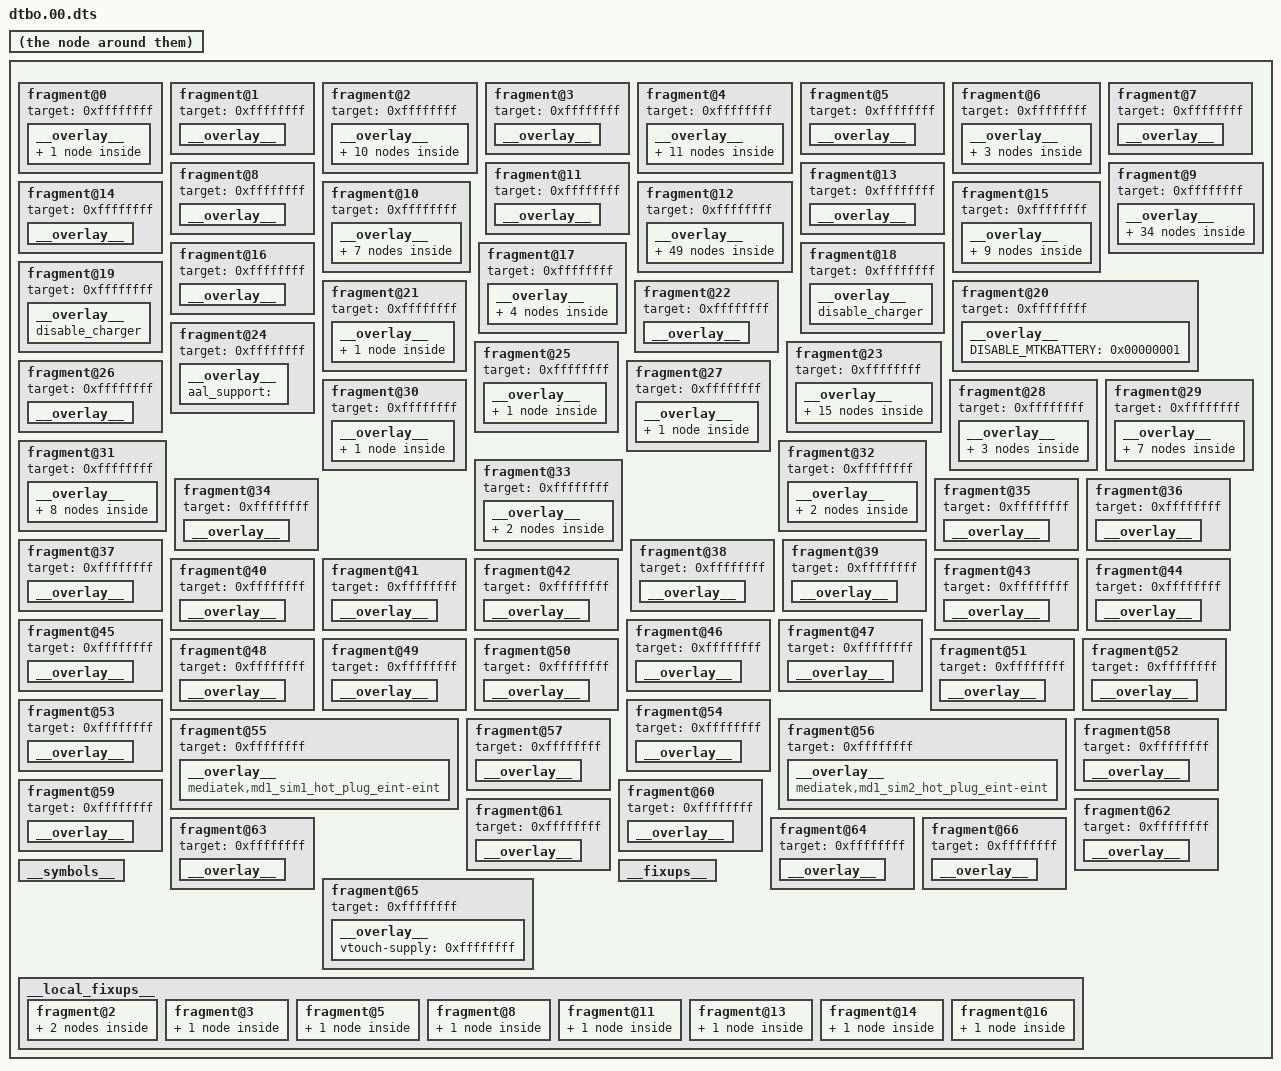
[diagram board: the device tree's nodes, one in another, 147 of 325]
/dts-v1/;
/plugin/;

 {
  fragment@0 {
    target = <0xffffffff>;
    __overlay__ {
      #address-cells = <0x00000002>;
      #size-cells = <0x00000002>;
      ranges = ;
      zmc-default {
        compatible = "mediatek,zone_movable_cma";
        size = <0x00000000 0xffc00000>;
        alignment = <0x00000000 0x10000000>;
        alloc-ranges = <0x00000000 0xc0000000 0x00000001 0x00000000>;
      };
    };
  };
  fragment@1 {
    target = <0xffffffff>;
    __overlay__ {
      atag,videolfb-fb_base_l = "^`P";
      atag,videolfb-fb_base_h = "";
      atag,videolfb-islcmfound = <0x00000001>;
      atag,videolfb-islcm_inited = "";
      atag,videolfb-fps = <0x00001770>;
      atag,videolfb-vramSize = <0x017bb000>;
      atag,videolfb-lcmname = "nt35595_fhd_dsi_cmd_truly_nt50358_drv";
    };
  };
  fragment@2 {
    target = <0xffffffff>;
    __overlay__ {
      led@0 {
        compatible = "mediatek,red";
        led_mode = "";
        data = <0x00000001>;
        pwm_config = "";
        linux,phandle = <0x00000046>;
        phandle = <0x00000046>;
      };
      led@1 {
        compatible = "mediatek,green";
        led_mode = "";
        data = <0x00000001>;
        pwm_config = "";
        linux,phandle = <0x00000047>;
        phandle = <0x00000047>;
      };
      led@2 {
        compatible = "mediatek,blue";
        led_mode = "";
        data = <0x00000001>;
        pwm_config = "";
        linux,phandle = <0x00000048>;
        phandle = <0x00000048>;
      };
      led@3 {
        compatible = "mediatek,jogball-backlight";
        led_mode = "";
        data = <0x00000001>;
        pwm_config = "";
        linux,phandle = <0x00000049>;
        phandle = <0x00000049>;
      };
      led@4 {
        compatible = "mediatek,keyboard-backlight";
        led_mode = "";
        data = <0x00000001>;
        pwm_config = "";
        linux,phandle = <0x0000004a>;
        phandle = <0x0000004a>;
      };
      led@5 {
        compatible = "mediatek,button-backlight";
        led_mode = "";
        data = <0x00000001>;
        pwm_config = "";
        linux,phandle = <0x0000004b>;
        phandle = <0x0000004b>;
      };
      led@6 {
        compatible = "mediatek,lcd-backlight";
        led_mode = <0x00000005>;
        data = <0x00000001>;
        pwm_config = <0x00000000 0x00000001 0x00000000 0x00000000 0x00000000>;
        linux,phandle = <0x0000004c>;
        phandle = <0x0000004c>;
      };
      vibrator@0 {
        compatible = "mediatek,vibrator";
        vib_timer = <0x00000019>;
        vib_limit = <0x00000009>;
        vib_vol = <0x00000009>;
        linux,phandle = <0x0000004d>;
        phandle = <0x0000004d>;
      };
      usb_c_pinctrl {
        compatible = "mediatek,usb_c_pinctrl";
        pinctrl-names = "usb_default", "redriver_c1_init", "redriver_c1_low", "redriver_c1_hiz", "redriver_c1_high", "redriver_c2_init", "redriver_c2_low", "redriver_c2_hiz", "redriver_c2_high", "u3_switch_sel1", "u3_switch_sel2", "u3_switch_enable", "u3_switch_disable";
        pinctrl-0 = <0x00000001>;
        pinctrl-1 = <0x00000002>;
        pinctrl-2 = <0x00000003>;
        pinctrl-3 = <0x00000004>;
        pinctrl-4 = <0x00000005>;
        pinctrl-5 = <0x00000006>;
        pinctrl-6 = <0x00000007>;
        pinctrl-7 = <0x00000008>;
        pinctrl-8 = <0x00000009>;
        pinctrl-9 = <0x0000000a>;
        pinctrl-10 = <0x0000000b>;
        pinctrl-11 = <0x0000000c>;
        pinctrl-12 = <0x0000000d>;
        status = "okay";
        linux,phandle = <0x0000004e>;
        phandle = <0x0000004e>;
        usb_switch-data {
          en_pin_num = "";
          en_pin_val = "";
          sel_pin_num = <0x000000b1>;
          sel_pin_val = <0x00000001>;
          c1_pin_num = "";
          c1_pin_val = "";
          c2_pin_num = "";
          c2_pin_val = "";
        };
      };
    };
  };
  fragment@3 {
    target = <0xffffffff>;
    __overlay__ {
      tpd-resolution = <0x00000438 0x00000780>;
      use-tpd-button = "";
      tpd-key-num = <0x00000003>;
      tpd-key-local = <0x0000008b 0x000000ac 0x0000009e 0x00000000>;
      tpd-key-dim-local = <0x0000005a 0x00000373 0x00000064 0x00000028 0x000000e6 0x00000373 0x00000064 0x00000028 0x00000172 0x00000373 0x00000064 0x00000028 0x00000000 0x00000000 0x00000000 0x00000000>;
      tpd-max-touch-num = <0x00000005>;
      tpd-filter-enable = <0x00000001>;
      tpd-filter-pixel-density = <0x00000092>;
      tpd-filter-custom-prameters = "";
      tpd-filter-custom-speed = "";
      pinctrl-names = "default", "state_eint_as_int", "state_eint_output0", "state_eint_output1", "state_rst_output0", "state_rst_output1";
      pinctrl-0 = <0x0000000e>;
      pinctrl-1 = <0x0000000f>;
      pinctrl-2 = <0x00000010>;
      pinctrl-3 = <0x00000011>;
      pinctrl-4 = <0x00000012>;
      pinctrl-5 = <0x00000013>;
      status = "okay";
    };
  };
  fragment@4 {
    target = <0xffffffff>;
    __overlay__ {
      eint0default {
        linux,phandle = <0x0000000e>;
        phandle = <0x0000000e>;
      };
      eint@0 {
        linux,phandle = <0x0000000f>;
        phandle = <0x0000000f>;
        pins_cmd_dat {
          pins = <0x00000100>;
          slew-rate = "";
          bias-disable = ;
        };
      };
      eintoutput0 {
        linux,phandle = <0x00000010>;
        phandle = <0x00000010>;
        pins_cmd_dat {
          pins = <0x00000100>;
          slew-rate = <0x00000001>;
          output-low = ;
        };
      };
      eintoutput1 {
        linux,phandle = <0x00000011>;
        phandle = <0x00000011>;
        pins_cmd_dat {
          pins = <0x00000100>;
          slew-rate = <0x00000001>;
          output-high = ;
        };
      };
      rstoutput0 {
        linux,phandle = <0x00000012>;
        phandle = <0x00000012>;
        pins_cmd_dat {
          pins = <0x00000200>;
          slew-rate = <0x00000001>;
          output-low = ;
        };
      };
      rstoutput1 {
        linux,phandle = <0x00000013>;
        phandle = <0x00000013>;
        pins_cmd_dat {
          pins = <0x00000200>;
          slew-rate = <0x00000001>;
          output-high = ;
        };
      };
    };
  };
  fragment@5 {
    target = <0xffffffff>;
    __overlay__ {
      accdet-mic-vol = <0x00000006>;
      headset-mode-setting = <0x00000500 0x00000500 0x00000001 0x000001f0 0x00000800 0x00000800 0x00000020 0x00000044>;
      accdet-plugout-debounce = <0x00000001>;
      accdet-mic-mode = <0x00000002>;
      headset-eint-level-pol = <0x00000008>;
      headset-three-key-threshold = <0x00000000 0x00000050 0x000000dc 0x00000190>;
      headset-three-key-threshold-CDD = <0x00000000 0x00000079 0x000000c0 0x00000258>;
      headset-four-key-threshold = <0x00000000 0x0000003a 0x00000079 0x000000c0 0x00000190>;
      pinctrl-names = "default", "state_eint_as_int";
      pinctrl-0 = <0x00000014>;
      pinctrl-1 = <0x00000015>;
      status = "okay";
    };
  };
  fragment@6 {
    target = <0xffffffff>;
    __overlay__ {
      accdetdefault {
        linux,phandle = <0x00000014>;
        phandle = <0x00000014>;
      };
      accdeteint@0 {
        linux,phandle = <0x00000015>;
        phandle = <0x00000015>;
        pins_cmd_dat {
          slew-rate = "";
          bias-disable = ;
        };
      };
    };
  };
  fragment@7 {
    target = <0xffffffff>;
    __overlay__ {
      core_1 = "enable";
      scp_sramSize = <0x00080000>;
    };
  };
  fragment@8 {
    target = <0xffffffff>;
    __overlay__ {
      pinctrl-names = "aud_clk_mosi_off", "aud_clk_mosi_on", "aud_dat_mosi_off", "aud_dat_mosi_on", "aud_dat_miso_off", "aud_dat_miso_on", "aud_smartpa_off", "aud_smartpa_on", "vow_dat_miso_off", "vow_dat_miso_on", "vow_clk_miso_off", "vow_clk_miso_on";
      pinctrl-0 = <0x00000016>;
      pinctrl-1 = <0x00000017>;
      pinctrl-2 = <0x00000018>;
      pinctrl-3 = <0x00000019>;
      pinctrl-4 = <0x0000001a>;
      pinctrl-5 = <0x0000001b>;
      pinctrl-6 = <0x0000001c>;
      pinctrl-7 = <0x0000001d>;
      pinctrl-8 = <0x0000001e>;
      pinctrl-9 = <0x0000001f>;
      pinctrl-10 = <0x00000020>;
      pinctrl-11 = <0x00000021>;
      status = "okay";
    };
  };
  fragment@9 {
    target = <0xffffffff>;
    __overlay__ {
      aud_clk_mosi_off {
        linux,phandle = <0x00000016>;
        phandle = <0x00000016>;
        pins_cmd0_dat {
          pins = <0x00008800>;
        };
      };
      aud_clk_mosi_on {
        linux,phandle = <0x00000017>;
        phandle = <0x00000017>;
        pins_cmd0_dat {
          pins = <0x00008801>;
        };
      };
      aud_dat_mosi_off {
        linux,phandle = <0x00000018>;
        phandle = <0x00000018>;
        pins_cmd1_dat {
          pins = <0x00008a00>;
        };
        pins_cmd2_dat {
          pins = <0x00008b00>;
        };
      };
      aud_dat_mosi_on {
        linux,phandle = <0x00000019>;
        phandle = <0x00000019>;
        pins_cmd1_dat {
          pins = <0x00008a01>;
        };
        pins_cmd2_dat {
          pins = <0x00008b01>;
        };
      };
      aud_dat_miso_off {
        linux,phandle = <0x0000001a>;
        phandle = <0x0000001a>;
        pins_cmd1_dat {
          pins = <0x00008e00>;
        };
        pins_cmd2_dat {
          pins = <0x00008f00>;
        };
      };
      aud_dat_miso_on {
        linux,phandle = <0x0000001b>;
        phandle = <0x0000001b>;
        pins_cmd1_dat {
          pins = <0x00008e01>;
        };
        pins_cmd2_dat {
          pins = <0x00008f01>;
        };
      };
      aud_pins_smartpa_off {
        linux,phandle = <0x0000001c>;
        phandle = <0x0000001c>;
        pins_cmd0_dat {
          pins = <0x0000ae00>;
        };
        pins_cmd1_dat {
          pins = <0x0000aa00>;
        };
        pins_cmd2_dat {
          pins = <0x0000ab00>;
        };
        pins_cmd3_dat {
          pins = <0x0000ac00>;
        };
      };
      aud_pins_smartpa_on {
        linux,phandle = <0x0000001d>;
        phandle = <0x0000001d>;
        pins_cmd0_dat {
          pins = <0x0000ae02>;
        };
        pins_cmd1_dat {
          pins = <0x0000aa02>;
        };
        pins_cmd2_dat {
          pins = <0x0000ab02>;
        };
        pins_cmd3_dat {
          pins = <0x0000ac02>;
        };
      };
      vow_dat_miso_off {
        linux,phandle = <0x0000001e>;
        phandle = <0x0000001e>;
        pins_cmd1_dat {
          pins = <0x00008e00>;
        };
      };
      vow_dat_miso_on {
        linux,phandle = <0x0000001f>;
        phandle = <0x0000001f>;
        pins_cmd1_dat {
          pins = <0x00008e04>;
        };
      };
      vow_clk_miso_off {
        linux,phandle = <0x00000020>;
        phandle = <0x00000020>;
        pins_cmd3_dat {
          pins = <0x00008f00>;
        };
      };
      vow_clk_miso_on {
        linux,phandle = <0x00000021>;
        phandle = <0x00000021>;
        pins_cmd3_dat {
          pins = <0x00008f04>;
        };
      };
    };
  };
  fragment@10 {
    target = <0xffffffff>;
    __overlay__ {
      consys_default {
        linux,phandle = <0x00000022>;
        phandle = <0x00000022>;
      };
      gpslna@0 {
        linux,phandle = <0x00000023>;
        phandle = <0x00000023>;
        pins_cmd_dat {
          pins = <0x00009b00>;
          slew-rate = "";
          bias-disable = ;
          output-low = ;
        };
      };
      gpslna@1 {
        linux,phandle = <0x00000024>;
        phandle = <0x00000024>;
        pins_cmd_dat {
          pins = <0x00009b00>;
          slew-rate = <0x00000001>;
          output-high = ;
        };
      };
      gpslna@2 {
        linux,phandle = <0x00000025>;
        phandle = <0x00000025>;
        pins_cmd_dat {
          pins = <0x00009b00>;
          slew-rate = <0x00000001>;
          output-low = ;
        };
      };
    };
  };
  fragment@11 {
    target = <0xffffffff>;
    __overlay__ {
      pinctrl-names = "default", "gps_lna_state_init", "gps_lna_state_oh", "gps_lna_state_ol";
      pinctrl-0 = <0x00000022>;
      pinctrl-1 = <0x00000023>;
      pinctrl-2 = <0x00000024>;
      pinctrl-3 = <0x00000025>;
      status = "okay";
    };
  };
  fragment@12 {
    target = <0xffffffff>;
    __overlay__ {
      cam0@0 {
        linux,phandle = <0x00000027>;
        phandle = <0x00000027>;
        pins_cmd_dat {
          pins = <0x00006500>;
          slew-rate = <0x00000001>;
          output-low = ;
        };
      };
      cam0@1 {
        linux,phandle = <0x00000028>;
        phandle = <0x00000028>;
        pins_cmd_dat {
          pins = <0x00006500>;
          slew-rate = <0x00000001>;
          output-high = ;
        };
      };
      cam0@2 {
        linux,phandle = <0x00000029>;
        phandle = <0x00000029>;
        pins_cmd_dat {
          pins = <0x00006100>;
          slew-rate = <0x00000001>;
          output-low = ;
        };
      };
      cam0@3 {
        linux,phandle = <0x0000002a>;
        phandle = <0x0000002a>;
        pins_cmd_dat {
          pins = <0x00006100>;
          slew-rate = <0x00000001>;
          output-high = ;
        };
      };
      cam1@0 {
        linux,phandle = <0x0000002b>;
        phandle = <0x0000002b>;
        pins_cmd_dat {
          pins = <0x00006600>;
          slew-rate = <0x00000001>;
          output-low = ;
        };
      };
      cam1@1 {
        linux,phandle = <0x0000002c>;
        phandle = <0x0000002c>;
        pins_cmd_dat {
          pins = <0x00006600>;
          slew-rate = <0x00000001>;
          output-high = ;
        };
      };
      cam1@2 {
        linux,phandle = <0x0000002d>;
        phandle = <0x0000002d>;
        pins_cmd_dat {
          pins = <0x00006200>;
          slew-rate = <0x00000001>;
          output-low = ;
        };
      };
      cam1@3 {
        linux,phandle = <0x0000002e>;
        phandle = <0x0000002e>;
        pins_cmd_dat {
          pins = <0x00006200>;
          slew-rate = <0x00000001>;
          output-high = ;
        };
      };
      cam2@0 {
        linux,phandle = <0x0000002f>;
        phandle = <0x0000002f>;
        pins_cmd_dat {
          pins = <0x00006d00>;
          slew-rate = <0x00000001>;
          output-low = ;
        };
      };
      cam2@1 {
        linux,phandle = <0x00000030>;
        phandle = <0x00000030>;
        pins_cmd_dat {
          pins = <0x00006d00>;
          slew-rate = <0x00000001>;
          output-high = ;
        };
      };
      cam2@3 {
        linux,phandle = <0x00000031>;
        phandle = <0x00000031>;
        pins_cmd_dat {
          pins = <0x00006b00>;
          slew-rate = <0x00000001>;
          output-low = ;
        };
      };
      cam2@4 {
        linux,phandle = <0x00000032>;
        phandle = <0x00000032>;
        pins_cmd_dat {
          pins = <0x00006b00>;
          slew-rate = <0x00000001>;
          output-high = ;
        };
      };
      cam0@vcam0 {
        linux,phandle = <0x00000033>;
        phandle = <0x00000033>;
        pins_cmd_dat {
          pins = <0x00005b00>;
          slew-rate = <0x00000001>;
          output-low = ;
        };
      };
      cam0@vcam1 {
        linux,phandle = <0x00000034>;
        phandle = <0x00000034>;
        pins_cmd_dat {
          pins = <0x00005b00>;
          slew-rate = <0x00000001>;
          output-high = ;
        };
      };
      cam2@vcam0 {
        linux,phandle = <0x00000035>;
        phandle = <0x00000035>;
        pins_cmd_dat {
          pins = <0x0000a900>;
          slew-rate = <0x00000001>;
          output-low = ;
        };
      };
      cam1@vcam1 {
        linux,phandle = <0x00000036>;
        phandle = <0x00000036>;
        pins_cmd_dat {
          pins = <0x0000a900>;
          slew-rate = <0x00000001>;
          output-high = ;
        };
      };
      cam1@vcam2 {
        linux,phandle = <0x00000037>;
        phandle = <0x00000037>;
        pins_cmd_dat {
          pins = <0x0000a900>;
          slew-rate = <0x00000001>;
          output-low = ;
        };
      };
      cam1@vcam3 {
        linux,phandle = <0x00000038>;
        phandle = <0x00000038>;
        pins_cmd_dat {
          pins = <0x0000a900>;
          slew-rate = <0x00000001>;
          output-high = ;
        };
      };
      camera_pins_cam0_mclk_on {
        linux,phandle = <0x0000003a>;
        phandle = <0x0000003a>;
        pins_cmd_dat {
          pins = <0x00006301>;
        };
      };
      camera_pins_cam0_mclk_off {
        linux,phandle = <0x00000039>;
        phandle = <0x00000039>;
        pins_cmd_dat {
          pins = <0x00006300>;
        };
      };
      camera_pins_cam1_mclk_off {
        linux,phandle = <0x0000003b>;
        phandle = <0x0000003b>;
        pins_cmd_dat {
          pins = <0x00006400>;
        };
      };
      camera_pins_cam1_mclk_on {
        linux,phandle = <0x0000003c>;
        phandle = <0x0000003c>;
        pins_cmd_dat {
          pins = <0x00006401>;
        };
      };
      camera_pins_cam2_mclk_off {
        linux,phandle = <0x0000003d>;
        phandle = <0x0000003d>;
        pins_cmd_dat {
          pins = <0x00006c00>;
        };
      };
      camera_pins_cam2_mclk_on {
        linux,phandle = <0x0000003e>;
        phandle = <0x0000003e>;
        pins_cmd_dat {
          pins = <0x00006c01>;
        };
      };
      camdefault {
        linux,phandle = <0x00000026>;
        phandle = <0x00000026>;
      };
    };
  };
  fragment@13 {
    target = <0xffffffff>;
    __overlay__ {
      pinctrl-names = "default", "cam0_rst0", "cam0_rst1", "cam0_pnd0", "cam0_pnd1", "cam1_rst0", "cam1_rst1", "cam1_pnd0", "cam1_pnd1", "cam2_rst0", "cam2_rst1", "cam2_pnd0", "cam2_pnd1", "cam_ldo_vcamd_0", "cam_ldo_vcamd_1", "cam_ldo_main2_vcamd_0", "cam_ldo_main2_vcamd_1", "cam_ldo_main2_vcama_0", "cam_ldo_main2_vcama_1", "cam0_mclk_off", "cam0_mclk_on", "cam1_mclk_off", "cam1_mclk_on", "cam2_mclk_off", "cam2_mclk_on";
      pinctrl-0 = <0x00000026>;
      pinctrl-1 = <0x00000027>;
      pinctrl-2 = <0x00000028>;
      pinctrl-3 = <0x00000029>;
      pinctrl-4 = <0x0000002a>;
      pinctrl-5 = <0x0000002b>;
      pinctrl-6 = <0x0000002c>;
      pinctrl-7 = <0x0000002d>;
      pinctrl-8 = <0x0000002e>;
      pinctrl-9 = <0x0000002f>;
      pinctrl-10 = <0x00000030>;
      pinctrl-11 = <0x00000031>;
      pinctrl-12 = <0x00000032>;
      pinctrl-13 = <0x00000033>;
      pinctrl-14 = <0x00000034>;
      pinctrl-15 = <0x00000035>;
      pinctrl-16 = <0x00000036>;
      pinctrl-17 = <0x00000037>;
      pinctrl-18 = <0x00000038>;
      pinctrl-19 = <0x00000039>;
      pinctrl-20 = <0x0000003a>;
      pinctrl-21 = <0x0000003b>;
      pinctrl-22 = <0x0000003c>;
      pinctrl-23 = <0x0000003d>;
      pinctrl-24 = <0x0000003e>;
      status = "okay";
    };
  };
  fragment@14 {
    target = <0xffffffff>;
    __overlay__ {
      pinctrl-names = "uart0_gpio_default", "uart0_rx_set", "uart0_rx_clear", "uart0_tx_set", "uart0_tx_clear";
      pinctrl-0 = <0x0000003f>;
      pinctrl-1 = <0x00000040>;
      pinctrl-2 = <0x00000041>;
      pinctrl-3 = <0x00000042>;
      pinctrl-4 = <0x00000043>;
      status = "okay";
    };
  };
  fragment@15 {
    target = <0xffffffff>;
    __overlay__ {
      uart0gpiodefault {
        linux,phandle = <0x0000003f>;
        phandle = <0x0000003f>;
      };
      uart0_rx_set@gpio95 {
        linux,phandle = <0x00000040>;
        phandle = <0x00000040>;
        pins_cmd_dat {
          pins = <0x00005f01>;
        };
      };
      uart0_rx_clear@gpio95 {
        linux,phandle = <0x00000041>;
        phandle = <0x00000041>;
        pins_cmd_dat {
          pins = <0x00005f00>;
          slew-rate = <0x00000001>;
          output-high = ;
        };
      };
      uart0_tx_set@gpio96 {
        linux,phandle = <0x00000042>;
        phandle = <0x00000042>;
        pins_cmd_dat {
          pins = <0x00006001>;
        };
      };
      uart0_tx_clear@gpio96 {
        linux,phandle = <0x00000043>;
        phandle = <0x00000043>;
        pins_cmd_dat {
          pins = <0x00006000>;
          slew-rate = <0x00000001>;
          output-high = ;
        };
      };
    };
  };
  fragment@16 {
    target = <0xffffffff>;
    __overlay__ {
      pinctrl-names = "irtx_gpio_led_default", "irtx_gpio_led_set";
      pinctrl-0 = <0x00000044>;
      pinctrl-1 = <0x00000045>;
      status = "okay";
    };
  };
  fragment@17 {
    target = <0xffffffff>;
    __overlay__ {
      irtx_gpio_led_def@gpio90 {
        linux,phandle = <0x00000044>;
        phandle = <0x00000044>;
        pins_cmd_dat {
          pins = <0x00005a00>;
          slew-rate = <0x00000001>;
          bias-disable = ;
          output-low = ;
          input-schmitt-enable = "";
        };
      };
      irtx_gpio_led_set@gpio90 {
        linux,phandle = <0x00000045>;
        phandle = <0x00000045>;
        pins_cmd_dat {
          pins = <0x00005a01>;
          slew-rate = <0x00000001>;
          output-high = ;
        };
      };
    };
  };
  fragment@18 {
    target = <0xffffffff>;
    __overlay__ {
      disable_charger = ;
    };
  };
  fragment@19 {
    target = <0xffffffff>;
    __overlay__ {
      disable_charger = ;
    };
  };
  fragment@20 {
    target = <0xffffffff>;
    __overlay__ {
      DISABLE_MTKBATTERY = <0x00000001>;
    };
  };
  fragment@21 {
    target = <0xffffffff>;
    __overlay__ {
      mt6370,intr_gpio_num = <0x0000000a>;
      mt6370,intr_gpio = <0xffffffff 0x0000000a 0x00000000>;
      charger {
        cv = <0x003d0900>;
      };
    };
  };
  fragment@22 {
    target = <0xffffffff>;
    __overlay__ {
      mt6370pd,intr_gpio_num = <0x00000029>;
      mt6370pd,intr_gpio = <0xffffffff 0x00000029 0x00000000>;
    };
  };
  fragment@23 {
    target = <0xffffffff>;
    __overlay__ {
      usb_default {
        linux,phandle = <0x00000001>;
        phandle = <0x00000001>;
      };
      c1_init {
        linux,phandle = <0x00000002>;
        phandle = <0x00000002>;
      };
      c1_low {
        linux,phandle = <0x00000003>;
        phandle = <0x00000003>;
      };
      c1_highz {
        linux,phandle = <0x00000004>;
        phandle = <0x00000004>;
      };
      c1_high {
        linux,phandle = <0x00000005>;
        phandle = <0x00000005>;
      };
      c2_init {
        linux,phandle = <0x00000006>;
        phandle = <0x00000006>;
      };
      c2_low {
        linux,phandle = <0x00000007>;
        phandle = <0x00000007>;
      };
      gc2_highz {
        linux,phandle = <0x00000008>;
        phandle = <0x00000008>;
      };
      c2_high {
        linux,phandle = <0x00000009>;
        phandle = <0x00000009>;
      };
      u3_sw_sel1 {
        linux,phandle = <0x0000000a>;
        phandle = <0x0000000a>;
        pins_cmd_dat {
          pins = <0x0000b100>;
          slew-rate = <0x00000001>;
          output-low = ;
        };
      };
      u3_sw_sel2 {
        linux,phandle = <0x0000000b>;
        phandle = <0x0000000b>;
        pins_cmd_dat {
          pins = <0x0000b100>;
          slew-rate = <0x00000001>;
          output-high = ;
        };
      };
      u3_sw_en {
        linux,phandle = <0x0000000c>;
        phandle = <0x0000000c>;
      };
      u3_sw_dis {
        linux,phandle = <0x0000000d>;
        phandle = <0x0000000d>;
      };
    };
  };
  fragment@24 {
    target = <0xffffffff>;
    __overlay__ {
      aal_support = "";
    };
  };
  fragment@25 {
    target = <0xffffffff>;
    __overlay__ {
      adc_channel@ {
        compatible = "mediatek,adc_channel";
        mediatek,temperature0 = "";
        mediatek,temperature1 = <0x00000001>;
        mediatek,adc_fdd_rf_params_dynamic_custom_ch = <0x00000002>;
        status = "okay";
      };
    };
  };
  fragment@26 {
    target = <0xffffffff>;
    __overlay__ {
      mediatek,clkbuf-quantity = <0x00000007>;
      mediatek,clkbuf-config = <0x00000002 0x00000001 0x00000001 0x00000002 0x00000000 0x00000000 0x00000001>;
      mediatek,clkbuf-driving-current = <0xffffffff 0xffffffff 0xffffffff 0xffffffff 0xffffffff 0xffffffff 0xffffffff>;
      status = "okay";
    };
  };
  fragment@27 {
    target = <0xffffffff>;
    __overlay__ {
      #address-cells = <0x00000001>;
      #size-cells = "";
      clock-frequency = <0x00061a80>;
      mediatek,use-open-drain = ;
      cap_touch@5d {
        compatible = "mediatek,cap_touch";
        reg = <0x0000005d>;
        status = "okay";
        linux,phandle = <0x0000004f>;
        phandle = <0x0000004f>;
      };
    };
  };
  fragment@28 {
    target = <0xffffffff>;
    __overlay__ {
      #address-cells = <0x00000001>;
      #size-cells = "";
      clock-frequency = <0x00061a80>;
      mediatek,use-open-drain = ;
      msensor@0c {
        compatible = "mediatek,msensor";
        reg = <0x0000000c>;
        status = "okay";
        linux,phandle = <0x00000050>;
        phandle = <0x00000050>;
      };
      alsps@51 {
        compatible = "mediatek,alsps";
        reg = <0x00000051>;
        status = "okay";
        linux,phandle = <0x00000051>;
        phandle = <0x00000051>;
      };
      barometer@77 {
        compatible = "mediatek,barometer";
        reg = <0x00000077>;
        status = "okay";
        linux,phandle = <0x00000052>;
        phandle = <0x00000052>;
      };
    };
  };
  fragment@29 {
    target = <0xffffffff>;
    __overlay__ {
      #address-cells = <0x00000001>;
      #size-cells = "";
      clock-frequency = <0x00061a80>;
      mediatek,use-open-drain = ;
      camera_main@1a {
        compatible = "mediatek,camera_main";
        reg = <0x0000001a>;
        status = "okay";
        linux,phandle = <0x00000053>;
        phandle = <0x00000053>;
      };
      camera_main_af@72 {
        compatible = "mediatek,camera_main_af";
        reg = <0x00000072>;
        status = "okay";
        linux,phandle = <0x00000054>;
        phandle = <0x00000054>;
      };
      camera_main_eeprom@50 {
        compatible = "mediatek,camera_main_eeprom";
        reg = <0x00000050>;
        status = "okay";
        linux,phandle = <0x00000055>;
        phandle = <0x00000055>;
      };
      camera_sub_two@1a {
        compatible = "mediatek,camera_sub_two";
        reg = <0x0000001a>;
        status = "okay";
        linux,phandle = <0x00000056>;
        phandle = <0x00000056>;
      };
      camera_sub_two_af@0c {
        compatible = "mediatek,camera_sub_two_af";
        reg = <0x0000000c>;
        status = "okay";
        linux,phandle = <0x00000057>;
        phandle = <0x00000057>;
      };
      camera_sub_two_eeprom@50 {
        compatible = "mediatek,camera_sub_two_eeprom";
        reg = <0x00000050>;
        status = "okay";
        linux,phandle = <0x00000058>;
        phandle = <0x00000058>;
      };
      ccu_sensor_i2c_main_hw@33 {
        compatible = "mediatek,ccu_sensor_i2c_main_hw";
        reg = <0x00000033>;
        status = "okay";
        linux,phandle = <0x00000059>;
        phandle = <0x00000059>;
      };
    };
  };
  fragment@30 {
    target = <0xffffffff>;
    __overlay__ {
      #address-cells = <0x00000001>;
      #size-cells = "";
      clock-frequency = <0x00061a80>;
      mediatek,use-open-drain = ;
      nfc@08 {
        compatible = "mediatek,nfc";
        reg = <0x00000008>;
        status = "okay";
        linux,phandle = <0x0000005a>;
        phandle = <0x0000005a>;
      };
    };
  };
  fragment@31 {
    target = <0xffffffff>;
    __overlay__ {
      #address-cells = <0x00000001>;
      #size-cells = "";
      clock-frequency = <0x00061a80>;
      mediatek,use-open-drain = ;
      camera_sub@35 {
        compatible = "mediatek,camera_sub";
        reg = <0x00000035>;
        status = "okay";
        linux,phandle = <0x0000005b>;
        phandle = <0x0000005b>;
      };
      camera_sub_eeprom@54 {
        compatible = "mediatek,camera_sub_eeprom";
        reg = <0x00000054>;
        status = "okay";
        linux,phandle = <0x0000005c>;
        phandle = <0x0000005c>;
      };
      camera_main_two@10 {
        compatible = "mediatek,camera_main_two";
        reg = <0x00000010>;
        status = "okay";
        linux,phandle = <0x0000005d>;
        phandle = <0x0000005d>;
      };
      camera_main_two_af@0c {
        compatible = "mediatek,camera_main_two_af";
        reg = <0x0000000c>;
        status = "okay";
        linux,phandle = <0x0000005e>;
        phandle = <0x0000005e>;
      };
      camera_main_two_hw@51 {
        compatible = "mediatek,camera_main_two_hw";
        reg = <0x00000051>;
        status = "okay";
        linux,phandle = <0x0000005f>;
        phandle = <0x0000005f>;
      };
      ccu_sensor_i2c_main2_hw@36 {
        compatible = "mediatek,ccu_sensor_i2c_main2_hw";
        reg = <0x00000036>;
        status = "okay";
        linux,phandle = <0x00000060>;
        phandle = <0x00000060>;
      };
      ccu_sensor_i2c_sub_hw@43 {
        compatible = "mediatek,ccu_sensor_i2c_sub_hw";
        reg = <0x00000043>;
        status = "okay";
        linux,phandle = <0x00000061>;
        phandle = <0x00000061>;
      };
      ccu_sensor_i2c_main3_hw@11 {
        compatible = "mediatek,ccu_sensor_i2c_main3_hw";
        reg = <0x00000011>;
        status = "okay";
        linux,phandle = <0x00000062>;
        phandle = <0x00000062>;
      };
    };
  };
  fragment@32 {
    target = <0xffffffff>;
    __overlay__ {
      #address-cells = <0x00000001>;
      #size-cells = "";
      clock-frequency = <0x0033e140>;
      mediatek,use-push-pull = ;
      usb_type_c@4e {
        compatible = "mediatek,usb_type_c";
        reg = <0x0000004e>;
        status = "okay";
        linux,phandle = <0x00000063>;
        phandle = <0x00000063>;
      };
      subpmic_pmu@34 {
        compatible = "mediatek,subpmic_pmu";
        reg = <0x00000034>;
        status = "okay";
        linux,phandle = <0x00000064>;
        phandle = <0x00000064>;
      };
    };
  };
  fragment@33 {
    target = <0xffffffff>;
    __overlay__ {
      #address-cells = <0x00000001>;
      #size-cells = "";
      clock-frequency = <0x00061a80>;
      mediatek,use-open-drain = ;
      slave_charger@4b {
        compatible = "mediatek,slave_charger";
        reg = <0x0000004b>;
        status = "okay";
        linux,phandle = <0x00000065>;
        phandle = <0x00000065>;
      };
      speaker_amp@34 {
        compatible = "mediatek,speaker_amp";
        reg = <0x00000034>;
        status = "okay";
        linux,phandle = <0x00000066>;
        phandle = <0x00000066>;
      };
    };
  };
  fragment@34 {
    target = <0xffffffff>;
    __overlay__ {
      #address-cells = <0x00000001>;
      #size-cells = "";
      clock-frequency = <0x00061a80>;
      mediatek,use-open-drain = ;
    };
  };
  fragment@35 {
    target = <0xffffffff>;
    __overlay__ {
      #address-cells = <0x00000001>;
      #size-cells = "";
      clock-frequency = <0x00061a80>;
      mediatek,use-open-drain = ;
    };
  };
  fragment@36 {
    target = <0xffffffff>;
    __overlay__ {
      #address-cells = <0x00000001>;
      #size-cells = "";
      clock-frequency = <0x00061a80>;
      mediatek,use-open-drain = ;
    };
  };
  fragment@37 {
    target = <0xffffffff>;
    __overlay__ {
      #address-cells = <0x00000001>;
      #size-cells = "";
      clock-frequency = <0x00061a80>;
      mediatek,use-open-drain = ;
    };
  };
  fragment@38 {
    target = <0xffffffff>;
    __overlay__ {
      #address-cells = <0x00000001>;
      #size-cells = "";
      clock-frequency = <0x00061a80>;
      mediatek,use-open-drain = ;
    };
  };
  fragment@39 {
    target = <0xffffffff>;
    __overlay__ {
      GPIO_SIM2_SIO = <0xffffffff 0x00000023 0x00000000>;
      GPIO_SIM2_SRST = <0xffffffff 0x00000024 0x00000000>;
      GPIO_SIM2_SCLK = <0xffffffff 0x00000025 0x00000000>;
      GPIO_SIM1_SCLK = <0xffffffff 0x00000026 0x00000000>;
      GPIO_SIM1_SRST = <0xffffffff 0x00000027 0x00000000>;
      GPIO_SIM1_SIO = <0xffffffff 0x00000028 0x00000000>;
      GPIO_SIM2_HOT_PLUG = <0xffffffff 0x0000002e 0x00000000>;
      GPIO_SIM1_HOT_PLUG = <0xffffffff 0x0000002f 0x00000000>;
    };
  };
  fragment@40 {
    target = <0xffffffff>;
    __overlay__ {
      gpio_init_default = [000000000000000000000000000000000000000100000001000000010000000100000000000000000000000000000001000000010000000100000002000000000000000100000000000000000000000000000001000000030000000000000000000000000000000100000001000000010000000400000000000000000000000000000001000000010000000000000005000000000000000000000000000000010000000000000000000000060000000000000000000000000000000100000001000000000000000700000000000000000000000000000001000000010000000000000008000000070000000000000000000000010000000100000000000000090000000000000000000000000000000100000001000000000000000a0000000000000000000000000000000100000001000000000000000b0000000300000000000000000000000100000001000000000000000c0000000300000000000000000000000100000001000000000000000d0000000400000000000000000000000100000001000000000000000e0000000400000001000000000000000000000000000000000000000f000000040000000000000000000000010000000100000000000000100000000400000001000000000000000000000000000000000000001100000000000000000000000000000001000000000000000000000012000000000000000100000001000000000000000000000000000000130000000000000001000000010000000000000000000000000000001400000000000000000000000000000001000000000000000000000015000000040000000000000000000000010000000000000000000000160000000400000000000000000000000100000000000000000000001700000000000000000000000000000001000000000000000000000018000000050000000000000000000000010000000000000000000000190000000500000000000000000000000100000000000000000000001a0000000500000000000000000000000100000000000000000000001b0000000500000001000000000000000000000000000000000000001c0000000500000000000000000000000100000001000000000000001d0000000100000001000000000000000000000000000000000000001e0000000100000000000000000000000100000001000000000000001f000000010000000000000000000000010000000100000000000000200000000100000000000000000000000100000001000000000000002100000001000000000000000000000001000000010000000000000022000000010000000000000000000000010000000100000000000000230000000100000000000000000000000100000001000000000000002400000001000000010000000000000000000000000000000000000025000000010000000100000000000000000000000000000000000000260000000100000001000000000000000000000000000000000000002700000001000000010000000000000000000000000000000000000028000000010000000000000000000000010000000100000000000000290000000000000000000000000000000100000001000000000000002a0000000000000001000000000000000000000000000000000000002b0000000100000001000000000000000000000000000000000000002c0000000100000000000000000000000100000000000000000000002d0000000100000001000000010000000000000000000000000000002e0000000100000000000000000000000100000001000000000000002f000000010000000000000000000000010000000100000000000000300000000100000000000000000000000100000001000000000000003100000001000000000000000000000001000000010000000000000032000000010000000000000000000000010000000100000000000000330000000100000000000000000000000100000001000000000000003400000001000000010000000000000001000000000000000000000035000000010000000100000000000000010000000000000000000000360000000100000001000000000000000100000000000000000000003700000001000000010000000000000001000000000000000000000038000000010000000100000000000000010000000000000000000000390000000100000001000000000000000100000000000000000000003a0000000000000000000000000000000100000000000000000000003b0000000100000000000000000000000100000000000000000000003c0000000100000000000000000000000100000000000000000000003d0000000100000000000000000000000100000000000000000000003e0000000100000000000000000000000100000000000000000000003f000000010000000000000000000000010000000000000000000000400000000100000000000000000000000100000000000000000000004100000002000000000000000000000001000000000000000000000042000000020000000000000000000000010000000000000000000000430000000100000000000000000000000100000000000000000000004400000001000000000000000000000001000000000000000000000045000000010000000100000000000000010000000000000000000000460000000100000001000000000000000100000000000000000000004700000001000000010000000000000001000000000000000000000048000000010000000100000000000000010000000000000000000000490000000100000001000000000000000100000000000000000000004a0000000100000001000000000000000100000000000000000000004b0000000100000001000000000000000100000000000000000000004c0000000100000001000000000000000100000000000000000000004d0000000100000001000000000000000100000000000000000000004e0000000100000001000000000000000100000000000000000000004f000000010000000100000000000000010000000000000000000000500000000100000001000000000000000100000000000000000000005100000001000000000000000000000001000000010000000000000052000000010000000000000000000000010000000100000000000000530000000100000000000000000000000100000001000000000000005400000001000000000000000000000001000000010000000000000055000000070000000100000000000000000000000000000000000000560000000700000000000000000000000100000000000000000000005700000007000000000000000000000001000000000000000000000058000000070000000000000000000000010000000000000000000000590000000100000000000000000000000100000000000000000000005a0000000100000001000000000000000000000000000000000000005b0000000000000001000000000000000000000000000000010000005c0000000100000001000000000000000100000000000000010000005d0000000100000000000000000000000100000001000000010000005e0000000100000000000000000000000100000001000000010000005f000000010000000000000000000000010000000100000000000000600000000100000001000000000000000000000000000000000000006100000000000000010000000000000000000000000000000000000062000000000000000100000000000000000000000000000000000000630000000100000001000000000000000000000000000000000000006400000001000000010000000000000000000000000000000000000065000000000000000100000001000000000000000000000000000000660000000000000001000000010000000000000000000000000000006700000001000000000000000000000001000000010000000000000068000000010000000000000000000000010000000100000000000000690000000100000000000000000000000100000001000000000000006a0000000100000000000000000000000100000001000000000000006b0000000000000001000000000000000000000000000000000000006c0000000100000001000000000000000000000000000000000000006d0000000000000001000000010000000000000000000000000000006e0000000300000000000000000000000100000001000000000000006f000000000000000000000000000000000000000000000000000000700000000300000001000000000000000000000000000000000000007100000000000000000000000000000001000000000000000000000072000000000000000000000000000000010000000000000000000000730000000000000000000000000000000100000000000000000000007400000000000000000000000000000001000000000000000000000075000000000000000000000000000000010000000000000000000000760000000000000000000000000000000100000000000000000000007700000000000000000000000000000001000000000000000000000078000000000000000000000000000000010000000000000000000000790000000000000000000000000000000100000000000000000000007a0000000100000000000000000000000100000001000000000000007b0000000100000000000000000000000100000001000000000000007c0000000100000001000000000000000000000000000000000000007d0000000100000000000000000000000100000001000000000000007e0000000100000000000000000000000100000001000000000000007f000000010000000000000000000000010000000100000000000000800000000100000000000000000000000100000001000000000000008100000001000000000000000000000001000000010000000000000082000000010000000000000000000000010000000100000000000000830000000100000000000000000000000100000000000000000000008400000001000000000000000000000001000000010000000000000085000000010000000100000001000000000000000000000000000000860000000100000000000000000000000100000000000000010000008700000001000000010000000000000000000000000000000000000088000000010000000100000000000000010000000000000000000000890000000100000001000000000000000100000000000000000000008a0000000100000001000000000000000000000000000000000000008b0000000100000001000000000000000100000000000000000000008c0000000100000000000000000000000000000000000000000000008d0000000100000000000000000000000000000000000000000000008e0000000100000000000000000000000000000000000000000000008f000000010000000000000000000000000000000000000000000000900000000100000000000000000000000100000000000000000000009100000001000000010000000100000000000000000000000000000092000000010000000000000000000000010000000000000000000000930000000100000001000000000000000000000000000000000000009400000001000000010000000000000000000000000000000000000095000000010000000100000000000000000000000000000000000000960000000000000001000000000000000000000000000000000000009700000000000000010000000000000000000000000000000000000098000000000000000100000000000000000000000000000000000000990000000000000001000000000000000000000000000000000000009a0000000100000001000000000000000000000000000000000000009b0000000000000001000000000000000000000000000000000000009c0000000000000001000000000000000000000000000000000000009d0000000000000001000000010000000000000000000000000000009e0000000100000001000000000000000000000000000000000000009f000000010000000100000000000000000000000000000000000000a0000000010000000100000000000000000000000000000000000000a1000000020000000000000000000000010000000000000000000000a2000000020000000100000001000000000000000000000000000000a3000000020000000100000000000000000000000000000000000000a4000000020000000100000000000000000000000000000000000000a5000000000000000100000001000000000000000000000000000000a6000000010000000100000000000000000000000000000000000000a7000000010000000100000000000000010000000000000000000000a8000000010000000100000000000000010000000000000000000000a9000000000000000100000000000000000000000000000000000000aa000000020000000100000000000000010000000000000000000000ab000000020000000100000000000000010000000000000000000000ac000000020000000100000000000000010000000000000000000000ad000000000000000000000000000000010000000000000000000000ae000000020000000000000000000000010000000000000000000000af000000000000000000000000000000000000000000000000000000b0000000000000000100000000000000000000000000000000000000b1000000000000000100000000000000000000000000000000000000b2000000000000000000000000000000010000000000000000000000b3000000000000000100000000000000000000000000000000000000b4000000000000000000000000000000010000000000000000000000b5000000000000000000000000000000010000000000000000000000b6000000000000000000000000000000010000000000000000000000b7000000000000000000000000000000010000000000000000000000b8000000000000000000000000000000010000000000000000000000b9000000000000000000000000000000010000000000000000000000ba000000000000000000000000000000010000000000000000000000bb000000000000000000000000000000010000000000000000000000bc000000000000000000000000000000010000000000000000000000bd000000000000000000000000000000010000000000000000000000be000000000000000000000000000000010000000000000000000000bf000000000000000000000000000000010000000000000000];
    };
  };
  fragment@41 {
    target = <0xffffffff>;
    __overlay__ {
      interrupt-parent = <0xffffffff>;
      interrupts = <0x00000000 0x00000008 0x00000000 0x00000000>;
      deb-gpios = <0xffffffff 0x00000000 0x00000000>;
      debounce = <0x0007d000>;
      status = "okay";
    };
  };
  fragment@42 {
    target = <0xffffffff>;
    __overlay__ {
      interrupt-parent = <0xffffffff>;
      interrupts = <0x00000001 0x00000002 0x00000001 0x00000000>;
      status = "okay";
    };
  };
  fragment@43 {
    target = <0xffffffff>;
    __overlay__ {
      interrupt-parent = <0xffffffff>;
      interrupts = <0x00000003 0x00000008 0x00000003 0x00000000>;
      deb-gpios = <0xffffffff 0x00000003 0x00000000>;
      debounce = <0x0003e800>;
      status = "okay";
    };
  };
  fragment@44 {
    target = <0xffffffff>;
    __overlay__ {
      interrupt-parent = <0xffffffff>;
      interrupts = <0x00000004 0x00000008 0x00000004 0x00000000>;
      status = "okay";
    };
  };
  fragment@45 {
    target = <0xffffffff>;
    __overlay__ {
      interrupt-parent = <0xffffffff>;
      interrupts = <0x00000005 0x00000004 0x00000005 0x00000000>;
      status = "okay";
    };
  };
  fragment@46 {
    target = <0xffffffff>;
    __overlay__ {
      interrupt-parent = <0xffffffff>;
      interrupts = <0x00000006 0x00000008 0x00000006 0x00000000>;
      status = "okay";
    };
  };
  fragment@47 {
    target = <0xffffffff>;
    __overlay__ {
      interrupt-parent = <0xffffffff>;
      interrupts = <0x00000007 0x00000008 0x00000007 0x00000000>;
      deb-gpios = <0xffffffff 0x00000007 0x00000000>;
      debounce = <0x0003e800>;
      status = "okay";
    };
  };
  fragment@48 {
    target = <0xffffffff>;
    __overlay__ {
      interrupt-parent = <0xffffffff>;
      interrupts = <0x00000009 0x00000008 0x00000009 0x00000000>;
      status = "okay";
    };
  };
  fragment@49 {
    target = <0xffffffff>;
    __overlay__ {
      interrupt-parent = <0xffffffff>;
      interrupts = <0x0000000a 0x00000008 0x0000000a 0x00000000>;
      status = "okay";
    };
  };
  fragment@50 {
    target = <0xffffffff>;
    __overlay__ {
      interrupt-parent = <0xffffffff>;
      interrupts = <0x00000014 0x00000004 0x00000014 0x00000000>;
      status = "okay";
    };
  };
  fragment@51 {
    target = <0xffffffff>;
    __overlay__ {
      interrupt-parent = <0xffffffff>;
      interrupts = <0x00000029 0x00000008 0x00000029 0x00000000>;
      status = "okay";
    };
  };
  fragment@52 {
    target = <0xffffffff>;
    __overlay__ {
      interrupt-parent = <0xffffffff>;
      interrupts = <0x0000002c 0x00000001 0x0000002c 0x00000001>;
      status = "okay";
    };
  };
  fragment@53 {
    target = <0xffffffff>;
    __overlay__ {
      interrupt-parent = <0xffffffff>;
      interrupts = <0x000000b6 0x00000004 0x000000be 0x00000000>;
      status = "okay";
    };
  };
  fragment@54 {
    target = <0xffffffff>;
    __overlay__ {
      interrupt-parent = <0xffffffff>;
      interrupts = <0x000000ba 0x00000008 0x000000ad 0x00000000>;
      status = "okay";
    };
  };
  fragment@55 {
    target = <0xffffffff>;
    __overlay__ {
      compatible = "mediatek,md1_sim1_hot_plug_eint-eint";
      interrupts = <0x00000000 0x00000004>;
      debounce = <0x00000000 0x000186a0>;
      dedicated = "";
      src_pin = <0x00000000 0x00000001>;
      sockettype = "";
      status = "okay";
    };
  };
  fragment@56 {
    target = <0xffffffff>;
    __overlay__ {
      compatible = "mediatek,md1_sim2_hot_plug_eint-eint";
      interrupts = <0x00000001 0x00000004>;
      debounce = <0x00000001 0x000186a0>;
      dedicated = <0x00000001 0x00000000>;
      src_pin = <0x00000001 0x00000002>;
      sockettype = <0x00000001 0x00000000>;
      status = "okay";
    };
  };
  fragment@57 {
    target = <0xffffffff>;
    __overlay__ {
      regulator-name = "vcama1";
      regulator-default-on = <0x00000001>;
      status = "okay";
    };
  };
  fragment@58 {
    target = <0xffffffff>;
    __overlay__ {
      regulator-name = "vcama2";
      regulator-default-on = <0x00000001>;
      status = "okay";
    };
  };
  fragment@59 {
    target = <0xffffffff>;
    __overlay__ {
      regulator-name = "vsim1";
      regulator-default-on = <0x00000001>;
      status = "okay";
    };
  };
  fragment@60 {
    target = <0xffffffff>;
    __overlay__ {
      regulator-name = "vsim2";
      regulator-default-on = <0x00000001>;
      status = "okay";
    };
  };
  fragment@61 {
    target = <0xffffffff>;
    __overlay__ {
      regulator-name = "vcamd";
      regulator-default-on = <0x00000001>;
      status = "okay";
    };
  };
  fragment@62 {
    target = <0xffffffff>;
    __overlay__ {
      regulator-name = "vcamio";
      regulator-default-on = <0x00000001>;
      status = "okay";
    };
  };
  fragment@63 {
    target = <0xffffffff>;
    __overlay__ {
      regulator-name = "vldo28";
      regulator-default-on = <0x00000001>;
      status = "okay";
    };
  };
  fragment@64 {
    target = <0xffffffff>;
    __overlay__ {
      vcama_sub-supply = <0xffffffff>;
      vcama-supply = <0xffffffff>;
      vcamd_sub-supply = <0xffffffff>;
      vcamio-supply = <0xffffffff>;
      vcamio_sub-supply = <0xffffffff>;
      vcamio_main2-supply = <0xffffffff>;
      vcamaf-supply = <0xffffffff>;
      vcamaf_sub-supply = <0xffffffff>;
      vcamaf_main2-supply = <0xffffffff>;
      status = "okay";
    };
  };
  fragment@65 {
    target = <0xffffffff>;
    __overlay__ {
      vtouch-supply = <0xffffffff>;
      status = "okay";
    };
  };
  fragment@66 {
    target = <0xffffffff>;
    __overlay__ {
      mediatek,kpd-key-debounce = <0x00000400>;
      mediatek,kpd-sw-pwrkey = <0x00000074>;
      mediatek,kpd-hw-pwrkey = <0x00000008>;
      mediatek,kpd-sw-rstkey = <0x00000066>;
      mediatek,kpd-hw-rstkey = <0x00000011>;
      mediatek,kpd-use-extend-type = "";
      mediatek,kpd-hw-map-num = <0x00000048>;
      mediatek,kpd-hw-init-map = "r", "s";
      mediatek,kpd-pwrkey-eint-gpio = "";
      mediatek,kpd-pwkey-gpio-din = "";
      mediatek,kpd-hw-dl-key0 = <0x00000001>;
      mediatek,kpd-hw-dl-key1 = "";
      mediatek,kpd-hw-dl-key2 = <0x00000008>;
      mediatek,kpd-hw-recovery-key = <0x00000001>;
      mediatek,kpd-hw-factory-key = "";
      status = "okay";
    };
  };
  __symbols__ {
    led0 = "/fragment@2/__overlay__/led@0";
    led1 = "/fragment@2/__overlay__/led@1";
    led2 = "/fragment@2/__overlay__/led@2";
    led3 = "/fragment@2/__overlay__/led@3";
    led4 = "/fragment@2/__overlay__/led@4";
    led5 = "/fragment@2/__overlay__/led@5";
    led6 = "/fragment@2/__overlay__/led@6";
    vibrator0 = "/fragment@2/__overlay__/vibrator@0";
    usb_c_pinctrl = "/fragment@2/__overlay__/usb_c_pinctrl";
    ctp_pins_default = "/fragment@4/__overlay__/eint0default";
    ctp_pins_eint_as_int = "/fragment@4/__overlay__/eint@0";
    ctp_pins_eint_output0 = "/fragment@4/__overlay__/eintoutput0";
    ctp_pins_eint_output1 = "/fragment@4/__overlay__/eintoutput1";
    ctp_pins_rst_output0 = "/fragment@4/__overlay__/rstoutput0";
    ctp_pins_rst_output1 = "/fragment@4/__overlay__/rstoutput1";
    accdet_pins_default = "/fragment@6/__overlay__/accdetdefault";
    accdet_pins_eint_as_int = "/fragment@6/__overlay__/accdeteint@0";
    aud_clk_mosi_off = "/fragment@9/__overlay__/aud_clk_mosi_off";
    aud_clk_mosi_on = "/fragment@9/__overlay__/aud_clk_mosi_on";
    aud_dat_mosi_off = "/fragment@9/__overlay__/aud_dat_mosi_off";
    aud_dat_mosi_on = "/fragment@9/__overlay__/aud_dat_mosi_on";
    aud_dat_miso_off = "/fragment@9/__overlay__/aud_dat_miso_off";
    aud_dat_miso_on = "/fragment@9/__overlay__/aud_dat_miso_on";
    aud_pins_smartpa_off = "/fragment@9/__overlay__/aud_pins_smartpa_off";
    aud_pins_smartpa_on = "/fragment@9/__overlay__/aud_pins_smartpa_on";
    vow_dat_miso_off = "/fragment@9/__overlay__/vow_dat_miso_off";
    vow_dat_miso_on = "/fragment@9/__overlay__/vow_dat_miso_on";
    vow_clk_miso_off = "/fragment@9/__overlay__/vow_clk_miso_off";
    vow_clk_miso_on = "/fragment@9/__overlay__/vow_clk_miso_on";
    consys_pins_default = "/fragment@10/__overlay__/consys_default";
    gpslna_pins_init = "/fragment@10/__overlay__/gpslna@0";
    gpslna_pins_oh = "/fragment@10/__overlay__/gpslna@1";
    gpslna_pins_ol = "/fragment@10/__overlay__/gpslna@2";
    camera_pins_cam0_rst_0 = "/fragment@12/__overlay__/cam0@0";
    camera_pins_cam0_rst_1 = "/fragment@12/__overlay__/cam0@1";
    camera_pins_cam0_pnd_0 = "/fragment@12/__overlay__/cam0@2";
    camera_pins_cam0_pnd_1 = "/fragment@12/__overlay__/cam0@3";
    camera_pins_cam1_rst_0 = "/fragment@12/__overlay__/cam1@0";
    camera_pins_cam1_rst_1 = "/fragment@12/__overlay__/cam1@1";
    camera_pins_cam1_pnd_0 = "/fragment@12/__overlay__/cam1@2";
    camera_pins_cam1_pnd_1 = "/fragment@12/__overlay__/cam1@3";
    camera_pins_cam2_rst_0 = "/fragment@12/__overlay__/cam2@0";
    camera_pins_cam2_rst_1 = "/fragment@12/__overlay__/cam2@1";
    camera_pins_cam2_pnd_0 = "/fragment@12/__overlay__/cam2@3";
    camera_pins_cam2_pnd_1 = "/fragment@12/__overlay__/cam2@4";
    camera_pins_cam0_vcamd_0 = "/fragment@12/__overlay__/cam0@vcam0";
    camera_pins_cam0_vcamd_1 = "/fragment@12/__overlay__/cam0@vcam1";
    camera_pins_cam2_vcamd_0 = "/fragment@12/__overlay__/cam2@vcam0";
    camera_pins_cam2_vcamd_1 = "/fragment@12/__overlay__/cam1@vcam1";
    camera_pins_cam2_vcama_0 = "/fragment@12/__overlay__/cam1@vcam2";
    camera_pins_cam2_vcama_1 = "/fragment@12/__overlay__/cam1@vcam3";
    camera_pins_cam0_mclk_on = "/fragment@12/__overlay__/camera_pins_cam0_mclk_on";
    camera_pins_cam0_mclk_off = "/fragment@12/__overlay__/camera_pins_cam0_mclk_off";
    camera_pins_cam1_mclk_off = "/fragment@12/__overlay__/camera_pins_cam1_mclk_off";
    camera_pins_cam1_mclk_on = "/fragment@12/__overlay__/camera_pins_cam1_mclk_on";
    camera_pins_cam2_mclk_off = "/fragment@12/__overlay__/camera_pins_cam2_mclk_off";
    camera_pins_cam2_mclk_on = "/fragment@12/__overlay__/camera_pins_cam2_mclk_on";
    camera_pins_default = "/fragment@12/__overlay__/camdefault";
    uart0_gpio_def_cfg = "/fragment@15/__overlay__/uart0gpiodefault";
    uart0_rx_set_cfg = "/fragment@15/__overlay__/uart0_rx_set@gpio95";
    uart0_rx_clr_cfg = "/fragment@15/__overlay__/uart0_rx_clear@gpio95";
    uart0_tx_set_cfg = "/fragment@15/__overlay__/uart0_tx_set@gpio96";
    uart0_tx_clr_cfg = "/fragment@15/__overlay__/uart0_tx_clear@gpio96";
    irtx_gpio_led_default = "/fragment@17/__overlay__/irtx_gpio_led_def@gpio90";
    irtx_gpio_led_set = "/fragment@17/__overlay__/irtx_gpio_led_set@gpio90";
    usb_default = "/fragment@23/__overlay__/usb_default";
    gpio_redriver_c1_init = "/fragment@23/__overlay__/c1_init";
    gpio_redriver_c1_low = "/fragment@23/__overlay__/c1_low";
    gpio_redriver_c1_hiz = "/fragment@23/__overlay__/c1_highz";
    gpio_redriver_c1_high = "/fragment@23/__overlay__/c1_high";
    gpio_redriver_c2_init = "/fragment@23/__overlay__/c2_init";
    gpio_redriver_c2_low = "/fragment@23/__overlay__/c2_low";
    gpio_redriver_c2_hiz = "/fragment@23/__overlay__/gc2_highz";
    gpio_redriver_c2_high = "/fragment@23/__overlay__/c2_high";
    gpio_u3_switch_sel1 = "/fragment@23/__overlay__/u3_sw_sel1";
    gpio_u3_switch_sel2 = "/fragment@23/__overlay__/u3_sw_sel2";
    gpio_u3_switch_enable = "/fragment@23/__overlay__/u3_sw_en";
    gpio_u3_switch_disable = "/fragment@23/__overlay__/u3_sw_dis";
    cap_touch_mtk = "/fragment@27/__overlay__/cap_touch@5d";
    msensor_mtk = "/fragment@28/__overlay__/msensor@0c";
    alsps_mtk = "/fragment@28/__overlay__/alsps@51";
    barometer_mtk = "/fragment@28/__overlay__/barometer@77";
    camera_main_mtk = "/fragment@29/__overlay__/camera_main@1a";
    camera_main_af_mtk = "/fragment@29/__overlay__/camera_main_af@72";
    camera_main_eeprom_mtk = "/fragment@29/__overlay__/camera_main_eeprom@50";
    camera_sub_two_mtk = "/fragment@29/__overlay__/camera_sub_two@1a";
    camera_sub_two_af_mtk = "/fragment@29/__overlay__/camera_sub_two_af@0c";
    camera_sub_two_eeprom_mtk = "/fragment@29/__overlay__/camera_sub_two_eeprom@50";
    ccu_sensor_i2c_main_hw_mtk = "/fragment@29/__overlay__/ccu_sensor_i2c_main_hw@33";
    nfc_mtk = "/fragment@30/__overlay__/nfc@08";
    camera_sub_mtk = "/fragment@31/__overlay__/camera_sub@35";
    camera_sub_eeprom_mtk = "/fragment@31/__overlay__/camera_sub_eeprom@54";
    camera_main_two_mtk = "/fragment@31/__overlay__/camera_main_two@10";
    camera_main_two_af_mtk = "/fragment@31/__overlay__/camera_main_two_af@0c";
    camera_main_two_hw_mtk = "/fragment@31/__overlay__/camera_main_two_hw@51";
    ccu_sensor_i2c_main2_hw_mtk = "/fragment@31/__overlay__/ccu_sensor_i2c_main2_hw@36";
    ccu_sensor_i2c_sub_hw_mtk = "/fragment@31/__overlay__/ccu_sensor_i2c_sub_hw@43";
    ccu_sensor_i2c_main3_hw_mtk = "/fragment@31/__overlay__/ccu_sensor_i2c_main3_hw@11";
    usb_type_c_mtk = "/fragment@32/__overlay__/usb_type_c@4e";
    subpmic_pmu_mtk = "/fragment@32/__overlay__/subpmic_pmu@34";
    slave_charger_mtk = "/fragment@33/__overlay__/slave_charger@4b";
    speaker_amp_mtk = "/fragment@33/__overlay__/speaker_amp@34";
  };
  __fixups__ {
    reserved_memory = "/fragment@0:target:0";
    chosen = "/fragment@1:target:0";
    odm = "/fragment@2:target:0";
    touch = "/fragment@3:target:0", "/fragment@42:target:0", "/fragment@65:target:0";
    pio = "/fragment@4:target:0", "/fragment@6:target:0", "/fragment@9:target:0", "/fragment@10:target:0", "/fragment@12:target:0", "/fragment@15:target:0", "/fragment@17:target:0", "/fragment@21/__overlay__:mt6370,intr_gpio:0", "/fragment@22/__overlay__:mt6370pd,intr_gpio:0", "/fragment@23:target:0", "/fragment@39/__overlay__:GPIO_SIM2_SIO:0", "/fragment@39/__overlay__:GPIO_SIM2_SRST:0", "/fragment@39/__overlay__:GPIO_SIM2_SCLK:0", "/fragment@39/__overlay__:GPIO_SIM1_SCLK:0", "/fragment@39/__overlay__:GPIO_SIM1_SRST:0", "/fragment@39/__overlay__:GPIO_SIM1_SIO:0", "/fragment@39/__overlay__:GPIO_SIM2_HOT_PLUG:0", "/fragment@39/__overlay__:GPIO_SIM1_HOT_PLUG:0", "/fragment@41/__overlay__:interrupt-parent:0", "/fragment@41/__overlay__:deb-gpios:0", "/fragment@42/__overlay__:interrupt-parent:0", "/fragment@43/__overlay__:interrupt-parent:0", "/fragment@43/__overlay__:deb-gpios:0", "/fragment@44/__overlay__:interrupt-parent:0", "/fragment@45/__overlay__:interrupt-parent:0", "/fragment@46/__overlay__:interrupt-parent:0", "/fragment@47/__overlay__:interrupt-parent:0", "/fragment@47/__overlay__:deb-gpios:0", "/fragment@48/__overlay__:interrupt-parent:0", "/fragment@49/__overlay__:interrupt-parent:0", "/fragment@50/__overlay__:interrupt-parent:0", "/fragment@51/__overlay__:interrupt-parent:0", "/fragment@52/__overlay__:interrupt-parent:0", "/fragment@53/__overlay__:interrupt-parent:0", "/fragment@54/__overlay__:interrupt-parent:0";
    accdet = "/fragment@5:target:0", "/fragment@47:target:0";
    scp = "/fragment@7:target:0";
    audgpio = "/fragment@8:target:0";
    consys = "/fragment@11:target:0";
    kd_camera_hw1 = "/fragment@13:target:0", "/fragment@64:target:0";
    apuart0 = "/fragment@14:target:0";
    irtx_pwm = "/fragment@16:target:0";
    lk_charger = "/fragment@18:target:0";
    charger = "/fragment@19:target:0";
    bat_gm30 = "/fragment@20:target:0";
    mt6370_pmu = "/fragment@21:target:0";
    mt6370_typec = "/fragment@22:target:0";
    disp_aal0 = "/fragment@24:target:0";
    auxadc = "/fragment@25:target:0";
    pmic_clock_buffer_ctrl = "/fragment@26:target:0";
    i2c0 = "/fragment@27:target:0";
    i2c1 = "/fragment@28:target:0";
    i2c2 = "/fragment@29:target:0";
    i2c3 = "/fragment@30:target:0";
    i2c4 = "/fragment@31:target:0";
    i2c5 = "/fragment@32:target:0";
    i2c6 = "/fragment@33:target:0";
    i2c7 = "/fragment@34:target:0";
    i2c8 = "/fragment@35:target:0";
    i2c9 = "/fragment@36:target:0";
    i2c10 = "/fragment@37:target:0";
    i2c11 = "/fragment@38:target:0";
    gpio_usage_mapping = "/fragment@39:target:0";
    gpio = "/fragment@40:target:0";
    mrdump_ext_rst = "/fragment@41:target:0";
    msdc1_ins = "/fragment@43:target:0";
    gyro = "/fragment@44:target:0";
    mse = "/fragment@45:target:0";
    als = "/fragment@46:target:0";
    rt9465_slave_chr = "/fragment@48:target:0";
    subpmic_pmu_eint = "/fragment@49:target:0";
    irq_nfc = "/fragment@50:target:0";
    tcpc_pd = "/fragment@51:target:0";
    dsi_te = "/fragment@52:target:0";
    main_pmic = "/fragment@53:target:0";
    smart_pa = "/fragment@54:target:0";
    md1_sim1_hot_plug_eint = "/fragment@55:target:0";
    md1_sim2_hot_plug_eint = "/fragment@56:target:0";
    mt_pmic_vcama1_ldo_reg = "/fragment@57:target:0", "/fragment@64/__overlay__:vcama_sub-supply:0";
    mt_pmic_vcama2_ldo_reg = "/fragment@58:target:0", "/fragment@64/__overlay__:vcama-supply:0";
    mt_pmic_vsim1_ldo_reg = "/fragment@59:target:0";
    mt_pmic_vsim2_ldo_reg = "/fragment@60:target:0";
    mt_pmic_vcamd_ldo_reg = "/fragment@61:target:0", "/fragment@64/__overlay__:vcamd_sub-supply:0";
    mt_pmic_vcamio_ldo_reg = "/fragment@62:target:0", "/fragment@64/__overlay__:vcamio-supply:0", "/fragment@64/__overlay__:vcamio_sub-supply:0", "/fragment@64/__overlay__:vcamio_main2-supply:0";
    mt_pmic_vldo28_ldo_reg = "/fragment@63:target:0", "/fragment@64/__overlay__:vcamaf-supply:0", "/fragment@64/__overlay__:vcamaf_sub-supply:0", "/fragment@64/__overlay__:vcamaf_main2-supply:0", "/fragment@65/__overlay__:vtouch-supply:0";
    keypad = "/fragment@66:target:0";
  };
  __local_fixups__ {
    fragment@2 {
      __overlay__ {
        usb_c_pinctrl {
          pinctrl-0 = "";
          pinctrl-1 = "";
          pinctrl-2 = "";
          pinctrl-3 = "";
          pinctrl-4 = "";
          pinctrl-5 = "";
          pinctrl-6 = "";
          pinctrl-7 = "";
          pinctrl-8 = "";
          pinctrl-9 = "";
          pinctrl-10 = "";
          pinctrl-11 = "";
          pinctrl-12 = "";
        };
      };
    };
    fragment@3 {
      __overlay__ {
        pinctrl-0 = "";
        pinctrl-1 = "";
        pinctrl-2 = "";
        pinctrl-3 = "";
        pinctrl-4 = "";
        pinctrl-5 = "";
      };
    };
    fragment@5 {
      __overlay__ {
        pinctrl-0 = "";
        pinctrl-1 = "";
      };
    };
    fragment@8 {
      __overlay__ {
        pinctrl-0 = "";
        pinctrl-1 = "";
        pinctrl-2 = "";
        pinctrl-3 = "";
        pinctrl-4 = "";
        pinctrl-5 = "";
        pinctrl-6 = "";
        pinctrl-7 = "";
        pinctrl-8 = "";
        pinctrl-9 = "";
        pinctrl-10 = "";
        pinctrl-11 = "";
      };
    };
    fragment@11 {
      __overlay__ {
        pinctrl-0 = "";
        pinctrl-1 = "";
        pinctrl-2 = "";
        pinctrl-3 = "";
      };
    };
    fragment@13 {
      __overlay__ {
        pinctrl-0 = "";
        pinctrl-1 = "";
        pinctrl-2 = "";
        pinctrl-3 = "";
        pinctrl-4 = "";
        pinctrl-5 = "";
        pinctrl-6 = "";
        pinctrl-7 = "";
        pinctrl-8 = "";
        pinctrl-9 = "";
        pinctrl-10 = "";
        pinctrl-11 = "";
        pinctrl-12 = "";
        pinctrl-13 = "";
        pinctrl-14 = "";
        pinctrl-15 = "";
        pinctrl-16 = "";
        pinctrl-17 = "";
        pinctrl-18 = "";
        pinctrl-19 = "";
        pinctrl-20 = "";
        pinctrl-21 = "";
        pinctrl-22 = "";
        pinctrl-23 = "";
        pinctrl-24 = "";
      };
    };
    fragment@14 {
      __overlay__ {
        pinctrl-0 = "";
        pinctrl-1 = "";
        pinctrl-2 = "";
        pinctrl-3 = "";
        pinctrl-4 = "";
      };
    };
    fragment@16 {
      __overlay__ {
        pinctrl-0 = "";
        pinctrl-1 = "";
      };
    };
  };
};
